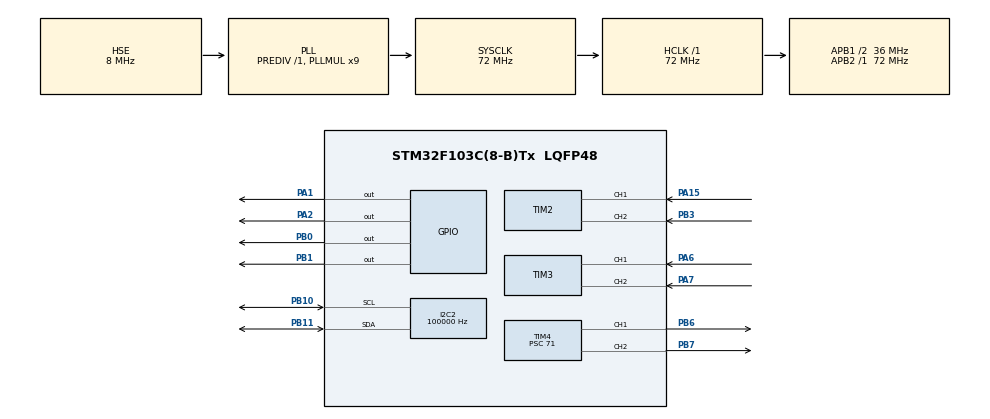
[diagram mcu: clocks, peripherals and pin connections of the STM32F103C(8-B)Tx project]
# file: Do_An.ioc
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I2C2.ClockSpeed=100000
Mcu.Family=STM32F1
Mcu.Name=STM32F103C(8-B)Tx
Mcu.Package=LQFP48
NVIC.PriorityGroup=NVIC_PRIORITYGROUP_4
PA1.Signal=GPIO_Output
PA13.Mode=Serial_Wire
PA13.Signal=SYS_JTMS-SWDIO
PA14.Mode=Serial_Wire
PA14.Signal=SYS_JTCK-SWCLK
PA15.Signal=S_TIM2_CH1_ETR
PA2.Signal=GPIO_Output
PA6.Signal=S_TIM3_CH1
PA7.Signal=S_TIM3_CH2
PB0.Signal=GPIO_Output
PB1.Signal=GPIO_Output
PB10.Mode=I2C
PB10.Signal=I2C2_SCL
PB11.Mode=I2C
PB11.Signal=I2C2_SDA
PB3.Signal=S_TIM2_CH2
PB6.Signal=S_TIM4_CH1
PB7.Signal=S_TIM4_CH2
PD0-OSC_IN.Mode=HSE-External-Oscillator
PD0-OSC_IN.Signal=RCC_OSC_IN
PD1-OSC_OUT.Mode=HSE-External-Oscillator
PD1-OSC_OUT.Signal=RCC_OSC_OUT
ProjectManager.HeapSize=0x200
ProjectManager.StackSize=0x400
ProjectManager.TargetToolchain=STM32CubeIDE
RCC.AHBFreq_Value=72000000
RCC.APB1CLKDivider=RCC_HCLK_DIV2
RCC.APB1Freq_Value=36000000
RCC.APB1TimFreq_Value=72000000
RCC.APB2Freq_Value=72000000
RCC.APB2TimFreq_Value=72000000
RCC.HCLKFreq_Value=72000000
RCC.PLLMUL=RCC_PLL_MUL9
RCC.PLLSourceVirtual=RCC_PLLSOURCE_HSE
RCC.SYSCLKFreq_VALUE=72000000
RCC.SYSCLKSource=RCC_SYSCLKSOURCE_PLLCLK
RCC.USBFreq_Value=72000000
SH.S_TIM2_CH1_ETR.0=TIM2_CH1,Encoder_Interface
SH.S_TIM2_CH2.0=TIM2_CH2,Encoder_Interface
SH.S_TIM3_CH1.0=TIM3_CH1,Encoder_Interface
SH.S_TIM3_CH2.0=TIM3_CH2,Encoder_Interface
SH.S_TIM4_CH1.0=TIM4_CH1,PWM Generation1 CH1
SH.S_TIM4_CH2.0=TIM4_CH2,PWM Generation2 CH2
TIM2.EncoderMode=TIM_ENCODERMODE_TI12
TIM3.EncoderMode=TIM_ENCODERMODE_TI12
TIM4.Channel-PWM\ Generation1\ CH1=TIM_CHANNEL_1
TIM4.Channel-PWM\ Generation2\ CH2=TIM_CHANNEL_2
TIM4.Period=7199
TIM4.Prescaler=71
VP_TIM4_VS_ClockSourceINT.Mode=Internal
board=custom

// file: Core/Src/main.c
/* USER CODE BEGIN Header */
/**
  ******************************************************************************
  * @file           : main.c
  * @brief          : Main program body
  ******************************************************************************
  * @attention
  *
  * <h2><center>&copy; Copyright (c) 2026 STMicroelectronics.
  * All rights reserved.</center></h2>
  *
  * This software component is licensed by ST under BSD 3-Clause license,
  * the "License"; You may not use this file except in compliance with the
  * License. You may obtain a copy of the License at:
  *                        opensource.org/licenses/BSD-3-Clause
  *
  ******************************************************************************
  */
/* USER CODE END Header */
#include "main.h"

/* USER CODE BEGIN Includes */
#include "robot_app.h"
/* USER CODE END Includes */

I2C_HandleTypeDef hi2c2;

TIM_HandleTypeDef htim2;
TIM_HandleTypeDef htim3;
TIM_HandleTypeDef htim4;

void SystemClock_Config(void);
static void MX_GPIO_Init(void);
static void MX_TIM3_Init(void);
static void MX_TIM4_Init(void);
static void MX_TIM2_Init(void);
static void MX_I2C2_Init(void);

int main(void)
{

  /* MCU Configuration--------------------------------------------------------*/

  /* Reset of all peripherals, Initializes the Flash interface and the Systick. */
   HAL_Init();

  /* Configure the system clock */
  SystemClock_Config();

  /* Initialize all configured peripherals */
  MX_GPIO_Init();
  MX_TIM3_Init();
  MX_TIM4_Init();
  MX_TIM2_Init();
  MX_I2C2_Init();
  /* USER CODE BEGIN 2 */
  if (RobotApp_Init(&htim3, &htim2, &htim4, &hi2c2) != HAL_OK) {
      Error_Handler();
  }
/* USER CODE END 2 */

  /* Infinite loop */
  while (1)
  {

    /* USER CODE BEGIN 3 */
    RobotApp_Process();
  }
/* USER CODE END 3 */
}

void SystemClock_Config(void)
{
  RCC_OscInitTypeDef RCC_OscInitStruct = {0};
  RCC_ClkInitTypeDef RCC_ClkInitStruct = {0};

  /** Initializes the RCC Oscillators according to the specified parameters
  * in the RCC_OscInitTypeDef structure.
  */
  RCC_OscInitStruct.OscillatorType = RCC_OSCILLATORTYPE_HSE;
  RCC_OscInitStruct.HSEState = RCC_HSE_ON;
  RCC_OscInitStruct.HSEPredivValue = RCC_HSE_PREDIV_DIV1;
  RCC_OscInitStruct.HSIState = RCC_HSI_ON;
  RCC_OscInitStruct.PLL.PLLState = RCC_PLL_ON;
  RCC_OscInitStruct.PLL.PLLSource = RCC_PLLSOURCE_HSE;
  RCC_OscInitStruct.PLL.PLLMUL = RCC_PLL_MUL9;
  if (HAL_RCC_OscConfig(&RCC_OscInitStruct) != HAL_OK)
  {
    Error_Handler();
  }
  /** Initializes the CPU, AHB and APB buses clocks
  */
  RCC_ClkInitStruct.ClockType = RCC_CLOCKTYPE_HCLK|RCC_CLOCKTYPE_SYSCLK
                              |RCC_CLOCKTYPE_PCLK1|RCC_CLOCKTYPE_PCLK2;
  RCC_ClkInitStruct.SYSCLKSource = RCC_SYSCLKSOURCE_PLLCLK;
  RCC_ClkInitStruct.AHBCLKDivider = RCC_SYSCLK_DIV1;
  RCC_ClkInitStruct.APB1CLKDivider = RCC_HCLK_DIV2;
  RCC_ClkInitStruct.APB2CLKDivider = RCC_HCLK_DIV1;

  if (HAL_RCC_ClockConfig(&RCC_ClkInitStruct, FLASH_LATENCY_2) != HAL_OK)
  {
    Error_Handler();
  }
}

static void MX_I2C2_Init(void)
{

  hi2c2.Instance = I2C2;
  hi2c2.Init.ClockSpeed = 100000;
  hi2c2.Init.DutyCycle = I2C_DUTYCYCLE_2;
  hi2c2.Init.OwnAddress1 = 0;
  hi2c2.Init.AddressingMode = I2C_ADDRESSINGMODE_7BIT;
  hi2c2.Init.DualAddressMode = I2C_DUALADDRESS_DISABLE;
  hi2c2.Init.OwnAddress2 = 0;
  hi2c2.Init.GeneralCallMode = I2C_GENERALCALL_DISABLE;
  hi2c2.Init.NoStretchMode = I2C_NOSTRETCH_DISABLE;
  if (HAL_I2C_Init(&hi2c2) != HAL_OK)
  {
    Error_Handler();
  }

}

static void MX_TIM2_Init(void)
{

  TIM_Encoder_InitTypeDef sConfig = {0};
  TIM_MasterConfigTypeDef sMasterConfig = {0};

  htim2.Instance = TIM2;
  htim2.Init.Prescaler = 0;
  htim2.Init.CounterMode = TIM_COUNTERMODE_UP;
  htim2.Init.Period = 65535;
  htim2.Init.ClockDivision = TIM_CLOCKDIVISION_DIV1;
  htim2.Init.AutoReloadPreload = TIM_AUTORELOAD_PRELOAD_DISABLE;
  sConfig.EncoderMode = TIM_ENCODERMODE_TI12;
  sConfig.IC1Polarity = TIM_ICPOLARITY_RISING;
  sConfig.IC1Selection = TIM_ICSELECTION_DIRECTTI;
  sConfig.IC1Prescaler = TIM_ICPSC_DIV1;
  sConfig.IC1Filter = 0;
  sConfig.IC2Polarity = TIM_ICPOLARITY_RISING;
  sConfig.IC2Selection = TIM_ICSELECTION_DIRECTTI;
  sConfig.IC2Prescaler = TIM_ICPSC_DIV1;
  sConfig.IC2Filter = 0;
  if (HAL_TIM_Encoder_Init(&htim2, &sConfig) != HAL_OK)
  {
    Error_Handler();
  }
  sMasterConfig.MasterOutputTrigger = TIM_TRGO_RESET;
  sMasterConfig.MasterSlaveMode = TIM_MASTERSLAVEMODE_DISABLE;
  if (HAL_TIMEx_MasterConfigSynchronization(&htim2, &sMasterConfig) != HAL_OK)
  {
    Error_Handler();
  }

}

static void MX_TIM3_Init(void)
{

  TIM_Encoder_InitTypeDef sConfig = {0};
  TIM_MasterConfigTypeDef sMasterConfig = {0};

  htim3.Instance = TIM3;
  htim3.Init.Prescaler = 0;
  htim3.Init.CounterMode = TIM_COUNTERMODE_UP;
  htim3.Init.Period = 65535;
  htim3.Init.ClockDivision = TIM_CLOCKDIVISION_DIV1;
  htim3.Init.AutoReloadPreload = TIM_AUTORELOAD_PRELOAD_DISABLE;
  sConfig.EncoderMode = TIM_ENCODERMODE_TI12;
  sConfig.IC1Polarity = TIM_ICPOLARITY_RISING;
  sConfig.IC1Selection = TIM_ICSELECTION_DIRECTTI;
  sConfig.IC1Prescaler = TIM_ICPSC_DIV1;
  sConfig.IC1Filter = 0;
  sConfig.IC2Polarity = TIM_ICPOLARITY_RISING;
  sConfig.IC2Selection = TIM_ICSELECTION_DIRECTTI;
  sConfig.IC2Prescaler = TIM_ICPSC_DIV1;
  sConfig.IC2Filter = 0;
  if (HAL_TIM_Encoder_Init(&htim3, &sConfig) != HAL_OK)
  {
    Error_Handler();
  }
  sMasterConfig.MasterOutputTrigger = TIM_TRGO_RESET;
  sMasterConfig.MasterSlaveMode = TIM_MASTERSLAVEMODE_DISABLE;
  if (HAL_TIMEx_MasterConfigSynchronization(&htim3, &sMasterConfig) != HAL_OK)
  {
    Error_Handler();
  }

}

static void MX_TIM4_Init(void)
{

  TIM_ClockConfigTypeDef sClockSourceConfig = {0};
  TIM_MasterConfigTypeDef sMasterConfig = {0};
  TIM_OC_InitTypeDef sConfigOC = {0};

  htim4.Instance = TIM4;
  htim4.Init.Prescaler = 71;
  htim4.Init.CounterMode = TIM_COUNTERMODE_UP;
  htim4.Init.Period = 7199;
  htim4.Init.ClockDivision = TIM_CLOCKDIVISION_DIV1;
  htim4.Init.AutoReloadPreload = TIM_AUTORELOAD_PRELOAD_DISABLE;
  if (HAL_TIM_Base_Init(&htim4) != HAL_OK)
  {
    Error_Handler();
  }
  sClockSourceConfig.ClockSource = TIM_CLOCKSOURCE_INTERNAL;
  if (HAL_TIM_ConfigClockSource(&htim4, &sClockSourceConfig) != HAL_OK)
  {
    Error_Handler();
  }
  if (HAL_TIM_PWM_Init(&htim4) != HAL_OK)
  {
    Error_Handler();
  }
  sMasterConfig.MasterOutputTrigger = TIM_TRGO_RESET;
  sMasterConfig.MasterSlaveMode = TIM_MASTERSLAVEMODE_DISABLE;
  if (HAL_TIMEx_MasterConfigSynchronization(&htim4, &sMasterConfig) != HAL_OK)
  {
    Error_Handler();
  }
  sConfigOC.OCMode = TIM_OCMODE_PWM1;
  sConfigOC.Pulse = 0;
  sConfigOC.OCPolarity = TIM_OCPOLARITY_HIGH;
  sConfigOC.OCFastMode = TIM_OCFAST_DISABLE;
  if (HAL_TIM_PWM_ConfigChannel(&htim4, &sConfigOC, TIM_CHANNEL_1) != HAL_OK)
  {
    Error_Handler();
  }
  if (HAL_TIM_PWM_ConfigChannel(&htim4, &sConfigOC, TIM_CHANNEL_2) != HAL_OK)
  {
    Error_Handler();
  }
  HAL_TIM_MspPostInit(&htim4);

}

static void MX_GPIO_Init(void)
{
  GPIO_InitTypeDef GPIO_InitStruct = {0};

  /* GPIO Ports Clock Enable */
  __HAL_RCC_GPIOD_CLK_ENABLE();
  __HAL_RCC_GPIOA_CLK_ENABLE();
  __HAL_RCC_GPIOB_CLK_ENABLE();

  /*Configure GPIO pin Output Level */
  HAL_GPIO_WritePin(GPIOA, GPIO_PIN_1|GPIO_PIN_2, GPIO_PIN_RESET);

  /*Configure GPIO pin Output Level */
  HAL_GPIO_WritePin(GPIOB, GPIO_PIN_0|GPIO_PIN_1, GPIO_PIN_RESET);

  /*Configure GPIO pins : PA1 PA2 */
  GPIO_InitStruct.Pin = GPIO_PIN_1|GPIO_PIN_2;
  GPIO_InitStruct.Mode = GPIO_MODE_OUTPUT_PP;
  GPIO_InitStruct.Pull = GPIO_NOPULL;
  GPIO_InitStruct.Speed = GPIO_SPEED_FREQ_LOW;
  HAL_GPIO_Init(GPIOA, &GPIO_InitStruct);

  /*Configure GPIO pins : PB0 PB1 */
  GPIO_InitStruct.Pin = GPIO_PIN_0|GPIO_PIN_1;
  GPIO_InitStruct.Mode = GPIO_MODE_OUTPUT_PP;
  GPIO_InitStruct.Pull = GPIO_NOPULL;
  GPIO_InitStruct.Speed = GPIO_SPEED_FREQ_LOW;
  HAL_GPIO_Init(GPIOB, &GPIO_InitStruct);

}

void Error_Handler(void)
{
  /* USER CODE BEGIN Error_Handler_Debug */
  if (htim4.Instance == TIM4) {
      __HAL_TIM_SET_COMPARE(&htim4, TIM_CHANNEL_1, 0);
      __HAL_TIM_SET_COMPARE(&htim4, TIM_CHANNEL_2, 0);
  }
  /* User can add his own implementation to report the HAL error return state */
  __disable_irq();
  while (1)
  {
  }
  /* USER CODE END Error_Handler_Debug */
}

/************************ (C) COPYRIGHT STMicroelectronics *****END OF FILE****/
